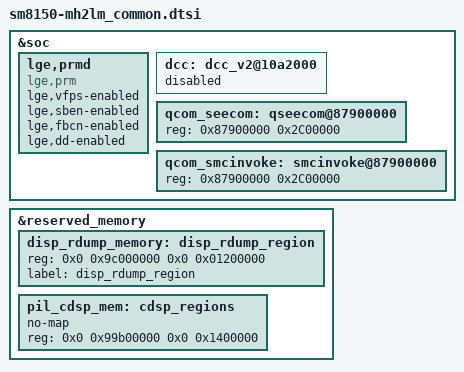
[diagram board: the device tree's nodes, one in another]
/*
 * Copyright (c) 2018, The Linux Foundation. All rights reserved.
 *
 * This program is free software; you can redistribute it and/or modify
 * it under the terms of the GNU General Public License version 2 and
 * only version 2 as published by the Free Software Foundation.
 *
 * This program is distributed in the hope that it will be useful,
 * but WITHOUT ANY WARRANTY; without even the implied warranty of
 * MERCHANTABILITY or FITNESS FOR A PARTICULAR PURPOSE.  See the
 * GNU General Public License for more details.
 */

#include "../../sm8150_common/sm8150_common.dtsi"

&soc {

	lge,prmd {
		compatible = "lge,prm";
		lge,vfps-enabled;
		lge,sben-enabled;
		lge,fbcn-enabled;
		lge,dd-enabled;
	};

};

&soc {
	dcc: dcc_v2@10a2000 {
		status = "disabled";
	};
};

// override sec app memory region for OIF
&soc {
	qcom_seecom: qseecom@87900000 {
		reg = <0x87900000 0x2C00000>;
	};

    qcom_smcinvoke: smcinvoke@87900000 {
		reg = <0x87900000 0x2C00000>;
    };
};

&reserved_memory {
	/delete-node/ cdsp_regions;
	/delete-node/ disp_rdump_region;

	disp_rdump_memory: disp_rdump_region {
			reg = <0x0 0x9c000000 0x0 0x01200000>;
			label = "disp_rdump_region";
	};

	pil_cdsp_mem: cdsp_regions {
		no-map;
		reg = <0x0 0x99b00000 0x0 0x1400000>;
	};
};
